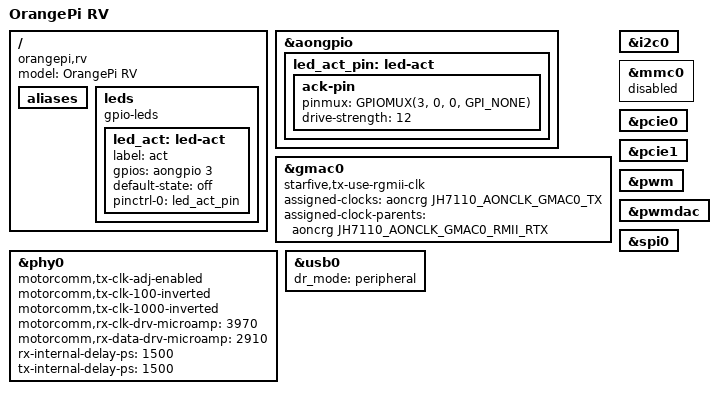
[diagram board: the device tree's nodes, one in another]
// SPDX-License-Identifier: GPL-2.0 OR MIT
/*
 * Copyright (C) 2022 StarFive Technology Co., Ltd.
 * Copyright (C) 2022 Emil Renner Berthing <kernel@esmil.dk>
 * Copyright (C) 2025 Hangfan Li <lihangfan@iscas.ac.cn>
 */

/dts-v1/;
#include "jh7110-common.dtsi"

/ {
	model = "OrangePi RV";
	compatible = "orangepi,rv", "starfive,jh7110";

	aliases {
	};

	leds {
		compatible = "gpio-leds";
		led_act: led-act {
			label = "act";
			gpios = <&aongpio 3 GPIO_ACTIVE_HIGH>;
			default-state = "off";
		};
	};
};

&aongpio {
	status = "okay";
	led_act_pin: led-act {
		ack-pin {
			pinmux = <GPIOMUX(3, 0, 0, GPI_NONE)>;
			drive-strength = <12>;
		};
	};
};

&gmac0 {
	starfive,tx-use-rgmii-clk;
	assigned-clocks = <&aoncrg JH7110_AONCLK_GMAC0_TX>;
	assigned-clock-parents = <&aoncrg JH7110_AONCLK_GMAC0_RMII_RTX>;
	status = "okay";
};

&i2c0 {
	status = "okay";
};

&led_act {
	status = "okay";
	pinctrl-names = "default";
	pinctrl-0 = <&led_act_pin>;
};

&mmc0 {
	status = "disabled";
};

&pcie0 {
	status = "okay";
};

&pcie1 {
	status = "okay";
};

&phy0 {
	motorcomm,tx-clk-adj-enabled;
	motorcomm,tx-clk-100-inverted;
	motorcomm,tx-clk-1000-inverted;
	motorcomm,rx-clk-drv-microamp = <3970>;
	motorcomm,rx-data-drv-microamp = <2910>;
	rx-internal-delay-ps = <1500>;
	tx-internal-delay-ps = <1500>;
};

&pwm {
	status = "okay";
};

&pwmdac {
	status = "okay";
};

&spi0 {
	status = "okay";
};

&usb0 {
	dr_mode = "peripheral";
	status = "okay";
};
